# 3066H register map
File version: 1.0
Registers are 32-bit, access per field, reset 0x0 unless marked. A register's access mark holds for its fields unless they carry their own. Offsets are from the block's base; [hi:lo] are bit positions.

## UART0 — UART0 peripheral interface
Base 0x14000000
Same registers: UART1 0x14001000, UART2 0x14002000, UART3 0x14003000, UART4 0x14004000, UART5 0x14005000, UART6 0x14006000, UART7 0x14007000
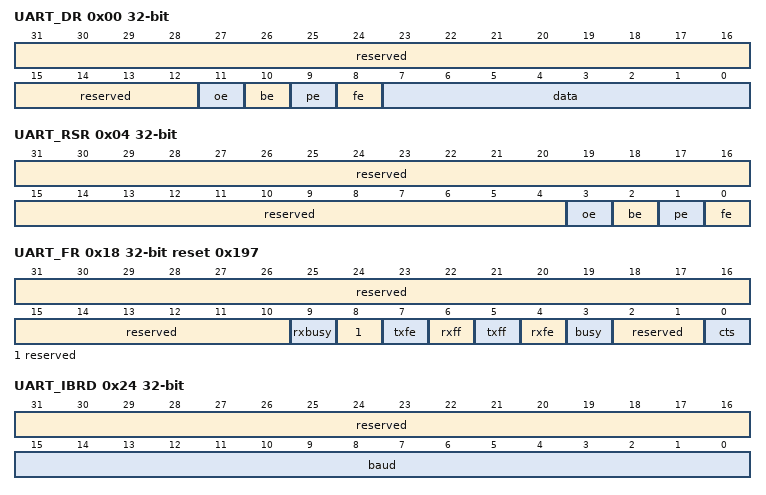
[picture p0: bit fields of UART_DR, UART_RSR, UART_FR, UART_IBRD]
0x00 UART_DR — UART_DR为UART数据寄存器，存放接收数据和发送数据，同时可以从该寄存器中读出接收状态。对于要发送的数据，占据8bit寄存器空间；对于接收到的数据，占据12bit寄存器空间。
  [31:12] reserved ro — 保留。
  [11] oe ro — 溢出错误。 0：无溢出错误； 1：有溢出错误，即接收FIFO满后接收到了新的数据。
  [10] be ro — Break错误。 0：无break错误； 1：有break错误，即接收数据持续低电平的时间比一个全字传输（包括起始位、数据位、校验位、停止位）还要长。
  [9] pe ro — 校验错误。 0：无校验错误； 1：有校验错误。
  [8] fe ro — 帧错误。 0：无帧错误； 1：有帧错误（错误的停止位）。
  [7:0] data rw — 接收数据和发送数据。
0x04 UART_RSR — UART_RSR为接收状态寄存器/错误清除寄存器。寄存器读时作为接收状态寄存器。寄存器写时作为错误清除寄存器。接收状态也可以从UART_DR中读出。从UART_DR中读出的break、frame、parity的状态信息要比从UART_RSR读出的信息优先级高（即UART_RSR[be]、UART_RSR[pe]、UART_RSR[fe]只有对UART_DR进行读操作才会刷新，UART_RSR[oe]不会刷新）。对UART_RSR寄存器的任何写操作都会对UART_RSR寄存器进行复位，清除错误。
  [31:4] reserved ro — 保留。
  [3] oe rw — 溢出错误。 0：无溢出错误； 1：溢出错误。 当接收FIFO满时，接收FIFO中的内容保持有效，因为不会有下一个数据写到接收FIFO中，只是移位寄存器会溢出。CPU必须立刻读数据以腾空FIFO。
  [2] be rw — break错误。 0：无break错误； 1：break错误。 break错误的条件：接收数据持续低电平的时间比一个全字传输（包括起始位、数据位、校验位、停止位）还要长。
  [1] pe rw — 校验错误。 0：无校验错误； 1：接收数据的校验错误。 FIFO模式下，该错误与FIFO顶部的数据相关联。
  [0] fe rw — 帧错误。 0：无帧错误； 1：接收到的数据的停止位错误（有效的停止位为1）。
0x18 UART_FR ro reset 0x197 — UART_FR为UART标志寄存器。
  [31:10] reserved — 保留。
  [9] rxbusy — UART接收忙闲状态位。 0：UART接收空闲； 1：UART正忙于接收数据。
  [8] reserved — 保留。
  [7] txfe — 发送FIFO空标志，该位的含义由UART_LCR_H[fen]的状态决定。 如果UART_LCR_H[fen]为0，则当发送保持寄存器空时该位置1； 如果UART_LCR_H[fen]为1，则当发送FIFO为空时该位置1。
  [6] rxff — 接收FIFO满标志，该位的含义由UART_LCR_H[fen]的状态决定。 如果UART_LCR_H[fen]为0，则当接收保持寄存器满时该位置1； 如果UART_LCR_H[fen]为1，则当接收FIFO为满时该位置1。
  [5] txff — 发送FIFO满标志，该位的含义由UART_LCR_H[fen]的状态决定。 如果UART_LCR_H[fen]为0，则当发送保持寄存器满时该位置1； 如果UART_LCR_H[fen]为1，当发送FIFO为满时该位置1。
  [4] rxfe — 接收FIFO空标志，该位的含义由UART_LCR_H[fen]的状态决定。 如果UART_LCR_H[fen]为0，则当接收保持寄存器空时该bit置1； 如果UART_LCR_H[fen]为1，则当接收FIFO为空时该位就置1。
  [3] busy — UART忙闲状态位。 0：UART空闲或者完成发送数据； 1：UART正忙于发送数据。 该位一旦置位，该状态一直保持到整个字节（包括所有的停止位）完全从移位寄存器中发送出去。 一旦发送FIFO非空该位就置位，不管UART使能与否。
  [2:1] reserved — 保留。
  [0] cts — CTS状态位。只对支持硬件流控的UART有效，为输入CTS管脚的状态取反。
0x24 UART_IBRD — UART_IBRD为整数波特率寄存器。
  [31:16] reserved ro — 保留。
  [15:0] baud divint rw — 整数波特率分频值。复位时全部清零。
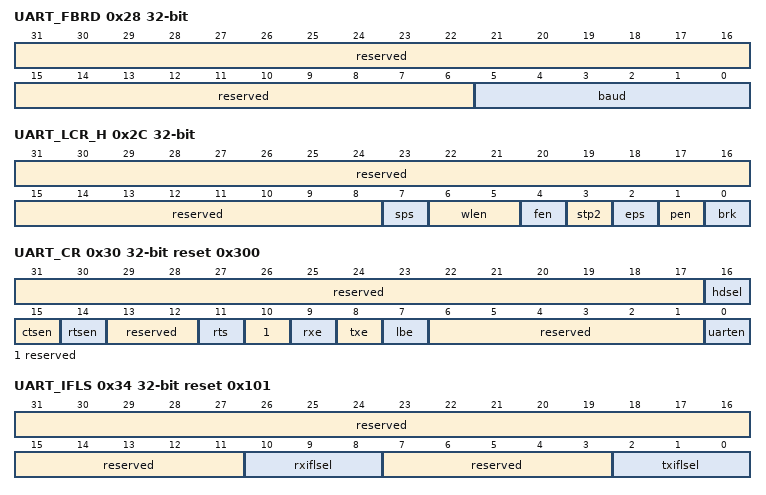
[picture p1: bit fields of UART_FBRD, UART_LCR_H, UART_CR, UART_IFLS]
0x28 UART_FBRD — UART_FBRD为小数波特率寄存器。
  [31:6] reserved ro — 保留。
  [5:0] baud divfrac rw — 小数波特率分频值。复位时全部清零。
0x2C UART_LCR_H — UART_LCR_H为线控寄存器，UART_LCR_H、UART_IBRD、UART_FBRD组成一个30bit宽的寄存器UART_LCR。UART_LCR只有在对UART_LCR_H写入后才会刷新。因此，如果更新UART_IBRD和UART_FBRD的内容，必须同时更新UART_LCR_H。
  [31:8] reserved ro — 保留。
  [7] sps rw — stick parity选择。 0：固定校验位禁止。具体校验位甴奇偶校验算法决定； 1：固定校验位使能。当配置为偶校验时，校验位固定为0，当配置为奇校验时，校验位固定为1。
  [6:5] wlen rw — 指示发送和接收一个帧内数据比特的数目。 00：5bit； 01：6bit； 10：7bit； 11：8bit。
  [4] fen rw — 发送和接收FIFO使能控制。 0：不使能发送和接收FIFO； 1：使能发送和接收FIFO。
  [3] stp2 rw — 发送帧尾停止位比特选择。 0：发送的帧尾接1bit停止位； 1：发送的帧尾接2bit停止位。 接收逻辑在接收时不检查2bit的停止位。
  [2] eps rw — 发送和接收过程中的奇偶校验选择。 0：在发送和接收过程中生成奇校验或检查奇校验； 1：在发送和接收过程中生成偶校验或检查偶校验。 当UART_LCR_H[pen]为0时，该位不起作用。
  [1] pen rw — 校验选择位。 0：不作校验； 1：发送方向产生校验，接收方向作校验检查。
  [0] brk rw — 发送break。 0：无效； 1：在完成当前数据的发送后，TXD连续输出低电平。 注意： 要正确的执行break命令，软件将该位置1的时间必须超过2个完整帧；在正常使用中，该位必须清零。
0x30 UART_CR reset 0x300 — UART_CR为UART控制寄存器。配置UART_CR遵循以下步骤：向UART_CR[uarten]写0，禁止UART。等待当前数据发送或接收结束。将UART_LCR_H[fen]清零以刷新FIFO。重新配置UART_CR。向UART_CR[uarten]写1，使能UART。
  [31:17] reserved ro — 保留。
  [16] hdsel rw — 硬件通信模式选择。 0：全双工通信； 1：单线半双工通信。
  [15] ctsen rw — CTS硬件流控使能。 0：不使能CTS硬件流控； 1：使能CTS硬件流控，只有当nUARTCTS信号有效时才发送数据。
  [14] rtsen rw — RTS硬件流控使能。 0：不使能RTS硬件流控； 1：使能RTS硬件流控，只有当接收FIFO有空间时才请求接收数据。
  [13:12] reserved ro — 保留。
  [11] rts rw — 请求发送。 该bit为UART modem状态输出信号nUARTRTS的取反。 0：输出信号不变； 1：即该bit配置为1，则输出信号为0。
  [10] reserved ro — 保留。
  [9] rxe rw — UART接收使能。 0：禁止； 1：使能。 在接收的过程中如果UART被禁止，则当前数据的接收就会在正常停止之前结束。
  [8] txe rw — UART发送使能。 0：禁止； 1：使能。 在发送的过程中如果UART被禁止，则当前数据的发送就会在正常停止之前结束。
  [7] lbe rw — 环回使能。 0：禁止； 1：UARTTXD输出内部环回到UARTRXD。
  [6:1] reserved ro — 保留。
  [0] uarten rw — UART使能。 0：禁止； 1：使能。 如果在发送和接收过程中将UART禁止，则会在正常停止之前结束当前数据的传送。
0x34 UART_IFLS reset 0x101 — UART_IFLS为中断FIFO水线选择寄存器，用于设置FIFO的中断（UART_TXINTR或UART_RXINTR）触发水线。FIFO的中断只有在FIFO内数据量通过设定水线时才触发。接收FIFO水线中断在接收FIFO内有效数据个数增加且通过设定水线时触发，触发一次。发送FIFO水线中断在发送FIFO内有效数据个数减少且通过设定水线时触发一次。
  [31:11] reserved ro — 保留。
  [10:8] rxiflsel rw — 配置接收FIFO的水线。当接收FIFO中的数据个数满足条件时，产生接收 FIFO中断（RXRIS）。如果使能了接收FIFO DMA功能，产生接收FIFO DMA burst传输请求。 0x0：大于或等于0； 0x1：大于或等于1； 0x2：大于或等于2； … 0x7：大于或等于7。 如果DMA控制器配置为搬移FIFO的数据，那么接收FIFO的水线需要大于DMA控制器的Burst长度。
  [7:3] reserved ro — 保留。
  [2:0] txiflsel rw — 配置发送FIFO的水线。当发送FIFO中的数据个数满足条件时，产生发送 FIFO中断（TXRIS）。如果使能了发送FIFO DMA功能，同时产生发送FIFO DMA burst传输请求。 0x0：等于0； 0x1：小于或等于1； 0x2：小于或等于2； … 0x7：小于或等于7。 如果DMA控制器配置为搬移FIFO的数据，那么发送FIFO的水线需要小于DMA控制器的Burst长度。
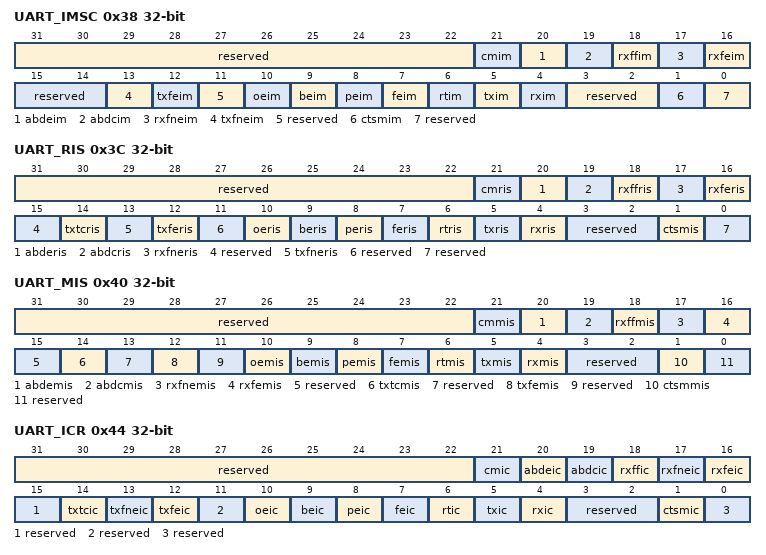
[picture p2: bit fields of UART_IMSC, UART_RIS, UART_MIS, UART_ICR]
0x38 UART_IMSC — UART_IMSC为中断屏蔽寄存器，用于屏蔽中断。当读寄存器时，读出的是相关中断屏蔽的当前值。当对寄存器写1时，不屏蔽相应中断。写0屏蔽相应中断。
  [31:22] reserved ro — 保留。
  [21] cmim rw — 字符匹配中断的屏蔽状态。 0：屏蔽该中断； 1：不屏蔽该中断。
  [20] abdeim rw — 自动波特率检测错误中断的屏蔽状态。 0：屏蔽该中断； 1：不屏蔽该中断。
  [19] abdcim rw — 自动波特率检测完成中断的屏蔽状态。 0：屏蔽该中断； 1：不屏蔽该中断。
  [18] rxffim rw — 接收FIFO满中断的屏蔽状态。 0：屏蔽该中断； 1：不屏蔽该中断。
  [17] rxfneim rw — 接收FIFO非空中断的屏蔽状态。 0：屏蔽该中断； 1：不屏蔽该中断。
  [16] rxfeim rw — 接收FIFO空中断的屏蔽状态。 0：屏蔽该中断； 1：不屏蔽该中断。
  [15:14] reserved ro — 保留。
  [13] txfneim rw — 发送FIFO非空中断的屏蔽状态。 0：屏蔽该中断； 1：不屏蔽该中断。
  [12] txfeim rw — 发送FIFO空中断的屏蔽状态。 0：屏蔽该中断； 1：不屏蔽该中断。
  [11] reserved ro — 保留。
  [10] oeim rw — 溢出错误中断的屏蔽状态。 0：屏蔽该中断； 1：不屏蔽该中断。
  [9] beim rw — break错误中断的屏蔽状态。 0：屏蔽该中断； 1：不屏蔽该中断。
  [8] peim rw — 校验中断的屏蔽状态。 0：屏蔽该中断； 1：不屏蔽该中断。
  [7] feim rw — 帧错误中断的屏蔽状态。 0：屏蔽该中断； 1：不屏蔽该中断。
  [6] rtim rw — 接收超时中断的屏蔽状态。 0：屏蔽该中断； 1：不屏蔽该中断。
  [5] txim rw — 发送中断的屏蔽状态。 0：屏蔽该中断； 1：不屏蔽该中断。
  [4] rxim rw — 接收中断的屏蔽状态。 0：屏蔽该中断； 1：不屏蔽该中断。
  [3:2] reserved ro — 保留。
  [1] ctsmim rw — CTS中断的屏蔽状态。 0：屏蔽该中断； 1：不屏蔽该中断。
  [0] reserved ro — 保留。
0x3C UART_RIS ro — UART_RIS为原始中断状态寄存器。
  [31:22] reserved — 保留。
  [21] cmris — 原始的字符匹配中断状态。 0：未产生中断； 1：已产生中断。
  [20] abderis — 原始的自动波特率检测错误中断状态。 0：未产生中断； 1：已产生中断。
  [19] abdcris — 原始的自动波特率检测完成中断状态。 0：未产生中断； 1：已产生中断。
  [18] rxffris — 原始的接收FIFO满中断状态。 0：未产生中断； 1：已产生中断。
  [17] rxfneris — 原始的接收FIFO非空中断状态。 0：未产生中断； 1：已产生中断。
  [16] rxferis — 原始的接收FIFO空中断状态。 0：未产生中断； 1：已产生中断。
  [15] reserved — 保留。
  [14] txtcris — 发送完成状态位。 0：发送完成条件未触发； 1：发送完成条件触发。
  [13] txfneris — 原始的发送FIFO非空中断状态。 0：未产生中断； 1：已产生中断。
  [12] txferis — 原始的发送FIFO空中断状态。 0：未产生中断； 1：已产生中断。
  [11] reserved — 保留。
  [10] oeris — 原始的溢出错误中断状态。 0：未产生中断； 1：已产生中断。
  [9] beris — 原始的break错误中断状态。 0：未产生中断； 1：已产生中断。
  [8] peris — 原始的校验中断状态。 0：未产生中断； 1：已产生中断。
  [7] feris — 原始的帧错误中断状态。 0：未产生中断； 1：已产生中断。
  [6] rtris — 原始的接收超时中断状态。 0：未产生中断； 1：已产生中断。 注意：只有当UART_IMSC[rtim]=1时，该位才能被置位，这样可以通过屏蔽位降低UART功耗。因此通过读该位和UART_MIS[rtmis]可得到同样的接收超时中断状态。
  [5] txris — 原始的发送水线中断状态。 0：未产生中断； 1：已产生中断。
  [4] rxris — 原始的接收水线中断状态。 0：未产生中断； 1：已产生中断。
  [3:2] reserved — 保留。
  [1] ctsmis — 原始的CTS中断状态。 0：未产生中断； 1：已产生中断。
  [0] reserved — 保留。
0x40 UART_MIS ro — UART_MIS为屏蔽后中断状态寄存器。
  [31:22] reserved — 保留。
  [21] cmmis — 屏蔽后的字符匹配中断状态。 0：未产生中断； 1：已产生中断。
  [20] abdemis — 屏蔽后的自动波特率检测错误中断状态。 0：未产生中断； 1：已产生中断。
  [19] abdcmis — 屏蔽后的自动波特率检测完成中断状态。 0：未产生中断； 1：已产生中断。
  [18] rxffmis — 屏蔽后的接收FIFO满中断状态。 0：未产生中断； 1：已产生中断。
  [17] rxfnemis — 屏蔽后的接收FIFO非空中断状态。 0：未产生中断； 1：已产生中断。
  [16] rxfemis — 屏蔽后的接收FIFO空中断状态。 0：未产生中断； 1：已产生中断。
  [15] reserved — 保留。
  [14] txtcmis — 屏蔽后的发送完成中断状态。 0：未产生中断； 1：已产生中断。
  [13] reserved — 保留。
  [12] txfemis — 屏蔽后的发送FIFO空中断状态。 0：未产生中断； 1：已产生中断。
  [11] reserved — 保留。
  [10] oemis — 屏蔽后的溢出错误中断状态。 0：未产生中断； 1：已产生中断。
  [9] bemis — 屏蔽后的break错误中断状态。 0：未产生中断； 1：已产生中断。
  [8] pemis — 屏蔽后的校验中断状态。 0：未产生中断； 1：已产生中断。
  [7] femis — 屏蔽后的帧错误中断状态。 0：未产生中断； 1：已产生中断。
  [6] rtmis — 屏蔽后的接收超时中断状态。 0：未产生中断； 1：已产生中断。
  [5] txmis — 屏蔽后的发送中断状态。 0：未产生中断； 1：已产生中断。
  [4] rxmis — 屏蔽后的接收中断状态。 0：未产生中断； 1：已产生中断。
  [3:2] reserved — 保留。
  [1] ctsmmis — 屏蔽后的CTS中断状态。 0：未产生中断； 1：已产生中断。
  [0] reserved — 保留。
0x44 UART_ICR — UART_ICR为中断清除寄存器，写1时相应的中断被清除，写0则不起作用。对于溢出错误中断，除了对此寄存器bit10写1以清除原始溢出错误中断外，还需要写UART_RSR[oe]以清除溢出错误状态。
  [31:22] reserved ro — 保留。
  [21] cmic wo — 清除字符匹配中断状态。 0：无效； 1：清除中断。
  [20] abdeic wo — 清除自动波特率检测错误中断状态。 0：无效； 1：清除中断。
  [19] abdcic wo — 清除自动波特率检测完成中断状态。 0：无效； 1：清除中断。
  [18] rxffic wo — 清除接收FIFO满中断状态。 0：无效； 1：清除中断。
  [17] rxfneic wo — 清除接收FIFO非空中断状态。 0：无效； 1：清除中断。
  [16] rxfeic wo — 清除接收FIFO空中断状态。 0：无效； 1：清除中断。
  [15] reserved ro — 保留。
  [14] txtcic wo — 清除发送完成中断状态。 0：无效； 1：清除中断。
  [13] txfneic wo — 清除发送FIFO非空中断状态。 0：无效； 1：清除中断。
  [12] txfeic wo — 清除发送FIFO空中断状态。 0：无效； 1：清除中断。
  [11] reserved ro — 保留。
  [10] oeic wo — 清除溢出错误中断。 0：无效； 1：清除中断。
  [9] beic wo — 清除break错误中断。 0：无效； 1：清除中断。
  [8] peic wo — 清除校验中断。 0：无效； 1：清除中断。
  [7] feic wo — 清除帧错误中断。 0：无效； 1：清除中断。
  [6] rtic wo — 清除接收超时中断。 0：无效； 1：清除中断。
  [5] txic wo — 清除发送中断。 0：无效； 1：清除中断。
  [4] rxic wo — 清除接收中断。 0：无效； 1：清除中断。
  [3:2] reserved ro — 保留。
  [1] ctsmic wo — 清除CTS中断。 0：无效； 1：清除中断。
  [0] reserved ro — 保留。
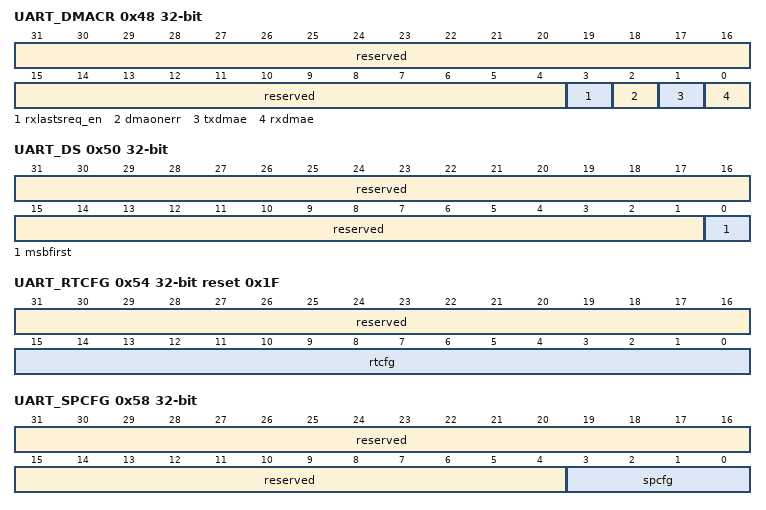
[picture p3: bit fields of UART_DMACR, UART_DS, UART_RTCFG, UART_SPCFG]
0x48 UART_DMACR — UART_DMACR为DMA控制寄存器，用于配置发送通道和接收通道的DMA使能。
  [31:4] reserved ro — 保留。
  [3] rxlastsreq_en rw — UART RX DMA支持最后一笔数据的REQ使能。使能打开后，传输最后一笔数据时会发出LASTREQ给DMA控制器。可以自动对DMA进行硬件流控。 0：禁止； 1：使能。
  [2] dmaonerr rw — UART错误中断（UARTEINTR）出现时的接收通道DMA使能控制。 0：当UART错误中断（UARTEINTR）有效时，接收通道DMA的请求输出（UARTRXDMASREQ或UARRTXDMABREQ）有效； 1：当UART错误中断（UARTEINTR）有效时，接收通道DMA的请求输出（UARTRXDMASREQ或UARRTXDMABREQ）无效。
  [1] txdmae rw — 发送通道的DMA使能控制。 0：禁止； 1：使能。
  [0] rxdmae rw — 接收通道的DMA使能控制。 0：禁止； 1：使能。
0x50 UART_DS — UART_DS为数据位序配置寄存器，用于配置数据位序。
  [31:1] reserved ro — 保留。
  [0] msbfirst rw — 最高有效位在前使能。 0：在起始位之后，首先使用数据位的LSB发送/接收数据； 1：在起始位之后，首先使用数据位的MSB发送/接收数据。
0x54 UART_RTCFG reset 0x1F — UART_RTCFG为接收超时时长配置寄存器，用于配置判断接收超时的条件。
  [31:16] reserved ro — 保留。
  [15:0] rtcfg rw — 配置接收超时时长，单位是bit时长。 接收超时时长=配置值+1。
0x58 UART_SPCFG — UART_SPCFG为过采样配置寄存器，用于配置过采样倍数。
  [31:4] reserved ro — 保留。
  [3:0] spcfg rw — 配置过采样倍数。 0x0：16倍过采样； 0x1：15倍过采样； 0x2：14倍过采样； 0x3：13倍过采样； 0x4：12倍过采样； 0x5：11倍过采样； 0x6：10倍过采样； 0x7：9倍过采样； 0x8：8倍过采样； 其他：禁止配置。
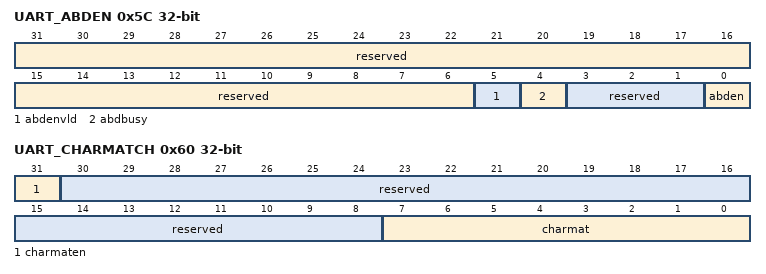
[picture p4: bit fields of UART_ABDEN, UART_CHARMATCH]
0x5C UART_ABDEN — UART_ABDEN为自动波特率检测使能寄存器，用于配置自动波特率检测使能。
  [31:6] reserved ro — 保留。
  [5] abdenvld ro — abden已经有效的标志。 0：abden还未生效； 1：abden已经生效，UART可以接收大写字符Z进行自动波特率检测。
  [4] abdbusy ro — 自动波特率检测忙标志。 0：不在进行自动波特率检测； 1：正在进行自动波特率检测。
  [3:1] reserved ro — 保留。
  [0] abden rw — 自动波特率检测使能。 0：禁止自动波特率检测； 1：使能自动波特率检测。 如果UART_CR[uarten]使能，且使能UART_CR[rxe]或UART_CR[txe]，则abden会被自动清零。
0x60 UART_CHARMATCH — UART_CHARMATCH为字符匹配配置寄存器，用于配置需要匹配的字符。
  [31] charmaten rw — 字符匹配检测使能。 0：禁止字符匹配检测； 1：使能字符匹配检测。
  [30:8] reserved ro — 保留。
  [7:0] charmat rw — 需要匹配的字符二进制。
